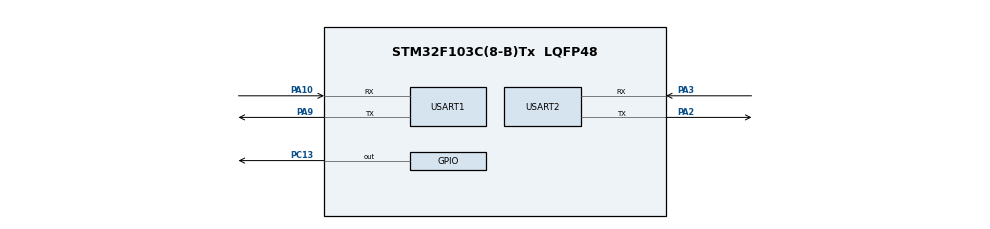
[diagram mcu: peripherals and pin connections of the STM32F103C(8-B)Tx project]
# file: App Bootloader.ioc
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Mcu.Family=STM32F1
Mcu.Name=STM32F103C(8-B)Tx
Mcu.Package=LQFP48
NVIC.PriorityGroup=NVIC_PRIORITYGROUP_4
NVIC.RCC_IRQn=true\:0\:0\:false\:false\:true\:true\:false\:true
NVIC.USART1_IRQn=true\:0\:0\:false\:false\:true\:true\:true\:true
NVIC.USART2_IRQn=true\:0\:0\:false\:false\:true\:true\:true\:true
PA10.Mode=Asynchronous
PA10.Signal=USART1_RX
PA13.Mode=Serial_Wire
PA13.Signal=SYS_JTMS-SWDIO
PA14.Mode=Serial_Wire
PA14.Signal=SYS_JTCK-SWCLK
PA2.Mode=Asynchronous
PA2.Signal=USART2_TX
PA3.Mode=Asynchronous
PA3.Signal=USART2_RX
PA9.Mode=Asynchronous
PA9.Signal=USART1_TX
PC13-TAMPER-RTC.Signal=GPIO_Output
PD0-OSC_IN.Mode=HSE-External-Oscillator
PD0-OSC_IN.Signal=RCC_OSC_IN
PD1-OSC_OUT.Mode=HSE-External-Oscillator
PD1-OSC_OUT.Signal=RCC_OSC_OUT
ProjectManager.HeapSize=0x200
ProjectManager.StackSize=0x400
ProjectManager.TargetToolchain=STM32CubeIDE
RCC.APB1Freq_Value=8000000
RCC.APB2Freq_Value=8000000
RCC.SYSCLKSource=RCC_SYSCLKSOURCE_HSE
USART1.VirtualMode=VM_ASYNC
USART2.VirtualMode=VM_ASYNC
board=custom

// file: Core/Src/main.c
/* USER CODE BEGIN Header */
/**
 ******************************************************************************
 * @file           : main.c
 * @brief          : Main program body(App2)
 ******************************************************************************
 * @attention
 *
 * Copyright (c) 2024 STMicroelectronics.
 * All rights reserved.
 *
 * This software is licensed under terms that can be found in the LICENSE file
 * in the root directory of this software component.
 * If no LICENSE file comes with this software, it is provided AS-IS.
 *
 ******************************************************************************
 */
/* USER CODE END Header */
#include "main.h"
#include "usart.h"
#include "gpio.h"

/* USER CODE BEGIN Includes */
#include "BL_Manager.h"
#include "BL_Manager_Config.h"

/* USER CODE END Includes */

void SystemClock_Config(void);

/* USER CODE BEGIN 0 */

HAL_UART_RxCpltCallback(UART_HandleTypeDef *huart) //For future work add this func to BL_Manager files not main
{
	if(BL_Jump_Status == BL_BEGIN_MATCH)
	{
		BL_Jump_Flag = BL_BEGIN_MATCH;
	}
	else
	{
		BL_Jump_Flag = BL_BEGIN_NOT_MATCH;
	}
}

/* USER CODE END 0 */

int main(void)
{

  /* MCU Configuration--------------------------------------------------------*/

  /* Reset of all peripherals, Initializes the Flash interface and the Systick. */
  HAL_Init();

  /* Configure the system clock */
  SystemClock_Config();

  /* Initialize all configured peripherals */
  MX_GPIO_Init();
  MX_USART1_UART_Init();
  MX_USART2_UART_Init();
  /* USER CODE BEGIN 2 */

    /*To connect with Bootloader if dedicated message is detected*/
	//BL_Manager();
  /* USER CODE END 2 */

  /* Infinite loop */
  /* USER CODE BEGIN WHILE */
	while (1)
	{
		/*Toggle led 13*/
		HAL_GPIO_WritePin(GPIOC, GPIO_PIN_13, GPIO_PIN_SET);
		//HAL_Delay(500); Cause conflict with flash derivers which results into bugs
		int i;
		for(i =0; i<1000000; i++);
		HAL_GPIO_WritePin(GPIOC, GPIO_PIN_13, GPIO_PIN_RESET);
		//HAL_Delay(500); Cause conflict with flash derivers which results into bugs
		for(i =0; i<1000000; i++);

		/*Check if there is OTA firmware update or not*/
		//BL_Response();
		//Jump_To_Address(FLASH_PAGE_BASE_ADDRESS_APP2); //for debug
    /* USER CODE END WHILE */

	}
}

void SystemClock_Config(void)
{
  RCC_OscInitTypeDef RCC_OscInitStruct = {0};
  RCC_ClkInitTypeDef RCC_ClkInitStruct = {0};

  /** Initializes the RCC Oscillators according to the specified parameters
  * in the RCC_OscInitTypeDef structure.
  */
  RCC_OscInitStruct.OscillatorType = RCC_OSCILLATORTYPE_HSE;
  RCC_OscInitStruct.HSEState = RCC_HSE_ON;
  RCC_OscInitStruct.PLL.PLLState = RCC_PLL_NONE;
  if (HAL_RCC_OscConfig(&RCC_OscInitStruct) != HAL_OK)
  {
    Error_Handler();
  }

  /** Initializes the CPU, AHB and APB buses clocks
  */
  RCC_ClkInitStruct.ClockType = RCC_CLOCKTYPE_HCLK|RCC_CLOCKTYPE_SYSCLK
                              |RCC_CLOCKTYPE_PCLK1|RCC_CLOCKTYPE_PCLK2;
  RCC_ClkInitStruct.SYSCLKSource = RCC_SYSCLKSOURCE_HSE;
  RCC_ClkInitStruct.AHBCLKDivider = RCC_SYSCLK_DIV1;
  RCC_ClkInitStruct.APB1CLKDivider = RCC_HCLK_DIV1;
  RCC_ClkInitStruct.APB2CLKDivider = RCC_HCLK_DIV1;

  if (HAL_RCC_ClockConfig(&RCC_ClkInitStruct, FLASH_LATENCY_0) != HAL_OK)
  {
    Error_Handler();
  }
}

void Error_Handler(void)
{
	__disable_irq();
	while (1)
	{
	}
}
